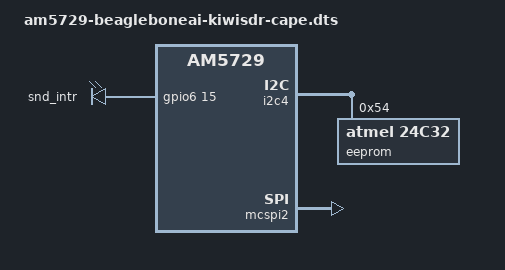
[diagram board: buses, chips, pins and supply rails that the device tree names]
/*
 * Copyright (C) 2014-2019 Texas Instruments Incorporated - http://www.ti.com/
 *
 * This program is free software; you can redistribute it and/or modify
 * it under the terms of the GNU General Public License version 2 as
 * published by the Free Software Foundation.
 */

#include "am5729-beagleboneai.dts"

#define KiwiSDR

    #define OUTPUT_SLOW         (1 << 19)

#ifdef KiwiSDR
    #define PIN_SPI_CS0         (OUTPUT_SLOW | PIN_OUTPUT_PULLUP)
    #define PIN_SPI_CLK	        (OUTPUT_SLOW | PIN_INPUT_PULLUP)
    #define PIN_SPI_MOSI        (OUTPUT_SLOW | PIN_OUTPUT_PULLDOWN)
    #define PIN_SPI_MISO        (PIN_INPUT_PULLDOWN)
#endif

/ {
	chosen {
		base_dtb = "am5729-beagleboneai-kiwisdr-cape.dts";
		base_dtb_timestamp = __TIMESTAMP__;
	};

	kiwisdr {
		compatible = "gpio-leds";
		pinctrl-names = "default";
		pinctrl-0 = <&cape_pins_kiwi>;

		snd_intr {
			label = "snd_intr";
			gpios = <&gpio6 15 GPIO_ACTIVE_HIGH>;
			default-state = "off";
		};
	};
};

&cape_pins {
	status = "disabled";
};

&dra7_pmx_core {
	cape_pins_kiwi: cape_pins_kiwi {
		pinctrl-single,pins = <
		
		// P8 connector
			DRA7XX_CORE_IOPAD(0x379C, PIN_INPUT_PULLUP | MUX_MODE14)    // AB8  P8.3    gpio1_24
			DRA7XX_CORE_IOPAD(0x37A0, PIN_INPUT_PULLUP | MUX_MODE14)    // AB5  P8.4    gpio1_25
			DRA7XX_CORE_IOPAD(0x378C, PIN_INPUT_PULLUP | MUX_MODE14)    // AC9  P8.5    gpio7_1
			DRA7XX_CORE_IOPAD(0x3790, PIN_INPUT_PULLUP | MUX_MODE14)    // AC3  P8.6    gpio7_2
			DRA7XX_CORE_IOPAD(0x36EC, PIN_INPUT_PULLUP | MUX_MODE14)    // G14  P8.7    gpio6_5  jtag tdi
			DRA7XX_CORE_IOPAD(0x36F0, PIN_INPUT_PULLUP | MUX_MODE14)    // F14  P8.8    gpio6_6  jtag td0
			DRA7XX_CORE_IOPAD(0x3698, PIN_INPUT_PULLUP | MUX_MODE14)    // E17  P8.9    gpio6_18 jtag tck
			DRA7XX_CORE_IOPAD(0x36E8, PIN_INPUT_PULLUP | MUX_MODE14)    // A13  P8.10   gpio6_4  jtag tms
			DRA7XX_CORE_IOPAD(0x3510, PIN_INPUT_PULLUP | MUX_MODE14)    // AH4  P8.11   gpio3_11 p811
			DRA7XX_CORE_IOPAD(0x350C, PIN_INPUT_PULLUP | MUX_MODE14)    // AG6  P8.12   gpio3_10 p812
			DRA7XX_CORE_IOPAD(0x3590, PIN_INPUT_PULLUP | MUX_MODE14)    // D3   P8.13   gpio4_11 p813
			DRA7XX_CORE_IOPAD(0x3598, PIN_INPUT_PULLUP | MUX_MODE14)    // D5   P8.14   gpio4_13 p814
			DRA7XX_CORE_IOPAD(0x3570, PIN_INPUT_PULLUP | MUX_MODE14)    // D1   P8.15a  gpio4_3  p815
			DRA7XX_CORE_IOPAD(0x35B4, PULL_DIS | MUX_MODE15)            // A3   P8.15b  gpio4_27
			DRA7XX_CORE_IOPAD(0x35BC, PIN_INPUT_PULLUP | MUX_MODE14)    // B4   P8.16   gpio4_29 p816
			DRA7XX_CORE_IOPAD(0x3624, PIN_INPUT_PULLUP | MUX_MODE14)    // A7   P8.17   gpio8_18 p817
			DRA7XX_CORE_IOPAD(0x3588, PIN_INPUT_PULLUP | MUX_MODE14)    // F5   P8.18   gpio4_9  p818
			DRA7XX_CORE_IOPAD(0x358C, PIN_INPUT_PULLUP | MUX_MODE14)    // E6   P8.19   gpio4_10 p819
			DRA7XX_CORE_IOPAD(0x3780, PIN_INPUT_PULLUP | MUX_MODE14)    // AC4  P8.20   gpio6_30
			DRA7XX_CORE_IOPAD(0x377C, PIN_INPUT_PULLUP | MUX_MODE14)    // AD4  P8.21   gpio6_29
			DRA7XX_CORE_IOPAD(0x3798, PIN_INPUT_PULLUP | MUX_MODE14)    // AD6  P8.22   gpio1_23
			DRA7XX_CORE_IOPAD(0x3794, PIN_INPUT_PULLUP | MUX_MODE14)    // AC8  P8.23   gpio1_22
			DRA7XX_CORE_IOPAD(0x3788, PIN_INPUT_PULLUP | MUX_MODE14)    // AC6  P8.24   gpio7_0
			DRA7XX_CORE_IOPAD(0x3784, PIN_INPUT_PULLUP | MUX_MODE14)    // AC7  P8.25   gpio6_31
			DRA7XX_CORE_IOPAD(0x35B8, PIN_INPUT_PULLUP | MUX_MODE14)    // B3   P8.26   gpio4_28 p826
			DRA7XX_CORE_IOPAD(0x35D8, PIN_INPUT_PULLUP | MUX_MODE14)    // E11  P8.27a  gpio4_23
			DRA7XX_CORE_IOPAD(0x3628, PIN_INPUT_PULLUP | MUX_MODE14)    // A8   P8.27b  gpio8_19
			DRA7XX_CORE_IOPAD(0x35C8, PIN_INPUT_PULLUP | MUX_MODE14)    // D11  P8.28a  gpio4_19
			DRA7XX_CORE_IOPAD(0x362C, PIN_INPUT_PULLUP | MUX_MODE14)    // C9   P8.28b  gpio8_20
			DRA7XX_CORE_IOPAD(0x35D4, PIN_INPUT_PULLUP | MUX_MODE14)    // C11  P8.29a  gpio4_22
			DRA7XX_CORE_IOPAD(0x3630, PIN_INPUT_PULLUP | MUX_MODE14)    // A9   P8.29b  gpio8_21
			DRA7XX_CORE_IOPAD(0x35CC, PIN_INPUT_PULLUP | MUX_MODE14)    // B10  P8.30a  gpio4_20
			DRA7XX_CORE_IOPAD(0x3634, PIN_INPUT_PULLUP | MUX_MODE14)    // B9   P8.30b  gpio8_22
			DRA7XX_CORE_IOPAD(0x3614, PIN_INPUT_PULLUP | MUX_MODE14)    // C8   P8.31a  gpio8_14
			DRA7XX_CORE_IOPAD(0x373C, PULL_DIS | MUX_MODE15)            // G16  P8.31b 
			DRA7XX_CORE_IOPAD(0x3618, PIN_INPUT_PULLUP | MUX_MODE14)    // C7   P8.32a  gpio8_15
			DRA7XX_CORE_IOPAD(0x3740, PULL_DIS | MUX_MODE15)            // D17  P8.32b 
			DRA7XX_CORE_IOPAD(0x3610, PIN_INPUT_PULLUP | MUX_MODE14)    // C6   P8.33a  gpio8_13
			DRA7XX_CORE_IOPAD(0x34E8, PIN_INPUT_PULLUP | MUX_MODE14)    // AF9  P8.33b  gpio3_1
			DRA7XX_CORE_IOPAD(0x3608, PIN_INPUT_PULLUP | MUX_MODE14)    // D8   P8.34a  gpio8_11
			DRA7XX_CORE_IOPAD(0x3564, PIN_INPUT_PULLUP | MUX_MODE14)    // G6   P8.34b  gpio4_0
			DRA7XX_CORE_IOPAD(0x360C, PIN_INPUT_PULLUP | MUX_MODE14)    // A5   P8.35a  gpio8_12
			DRA7XX_CORE_IOPAD(0x34E4, PIN_INPUT_PULLUP | MUX_MODE14)    // AD9  P8.35b  gpio3_0
			DRA7XX_CORE_IOPAD(0x3604, PIN_INPUT_PULLUP | MUX_MODE14)    // D7   P8.36a  gpio8_10
			DRA7XX_CORE_IOPAD(0x3568, PIN_INPUT_PULLUP | MUX_MODE14)    // F2   P8.36b  gpio4_1
			DRA7XX_CORE_IOPAD(0x35FC, PIN_INPUT_PULLUP | MUX_MODE14)    // E8   P8.37a  gpio8_8
			DRA7XX_CORE_IOPAD(0x3738, PULL_DIS | MUX_MODE15)            // A21  P8.37b 
			DRA7XX_CORE_IOPAD(0x3600, PIN_INPUT_PULLUP | MUX_MODE14)    // D9   P8.38a  gpio8_9
			DRA7XX_CORE_IOPAD(0x3734, PULL_DIS | MUX_MODE15)            // C18  P8.38b 
			DRA7XX_CORE_IOPAD(0x35F4, PIN_INPUT_PULLUP | MUX_MODE14)    // F8   P8.39   gpio8_6
			DRA7XX_CORE_IOPAD(0x35F8, PIN_INPUT_PULLUP | MUX_MODE14)    // E7   P8.40   gpio8_7
			DRA7XX_CORE_IOPAD(0x35EC, PIN_INPUT_PULLUP | MUX_MODE14)    // E9   P8.41   gpio8_4
			DRA7XX_CORE_IOPAD(0x35F0, PIN_INPUT_PULLUP | MUX_MODE14)    // F9   P8.42   gpio8_5
			DRA7XX_CORE_IOPAD(0x35E4, PIN_INPUT_PULLUP | MUX_MODE14)    // F10  P8.43   gpio8_2
			DRA7XX_CORE_IOPAD(0x35E8, PIN_INPUT_PULLUP | MUX_MODE14)    // G11  P8.44   gpio8_3
			DRA7XX_CORE_IOPAD(0x35DC, PIN_INPUT_PULLUP | MUX_MODE14)    // F11  P8.45a  gpio8_0
			DRA7XX_CORE_IOPAD(0x361C, PIN_INPUT_PULLUP | MUX_MODE14)    // B7   P8.45b  gpio8_16
			DRA7XX_CORE_IOPAD(0x35E0, PIN_INPUT_PULLUP | MUX_MODE14)    // G10  P8.46a  gpio8_1
			DRA7XX_CORE_IOPAD(0x3638, PIN_INPUT_PULLUP | MUX_MODE14)    // A10  P8.46b  gpio8_23

        // P9 connector
			DRA7XX_CORE_IOPAD(0x372C, PULL_DIS | MUX_MODE15)            // B19  P9.11a  
			DRA7XX_CORE_IOPAD(0x3620, PIN_INPUT_PULLDOWN | MUX_MODE14)  // B8   P9.11b  gpio8_17 p911
			DRA7XX_CORE_IOPAD(0x36AC, PIN_OUTPUT_PULLUP | MUX_MODE14)   // B14  P9.12   gpio5_0 fpga_pgm
			DRA7XX_CORE_IOPAD(0x3730, MUX_MODE15)                       // C17  P9.13a  
			DRA7XX_CORE_IOPAD(0x3680, PIN_INPUT_PULLDOWN | MUX_MODE14)  // AB10 P9.13b  gpio6_12 p913 (not connected on rev A1)
			DRA7XX_CORE_IOPAD(0x35AC, PIN_INPUT_PULLUP | MUX_MODE14)    // D6   P9.14   gpio4_25 fpga_init
			DRA7XX_CORE_IOPAD(0x3514, PIN_INPUT_PULLUP | MUX_MODE14)    // AG4  P9.15   gpio3_12 p915

            // spi2
			DRA7XX_CORE_IOPAD(0x35B0, PIN_OUTPUT_PULLUP | MUX_MODE14)   // C5   P9.16   gpio4_26 spi2_cs1
			DRA7XX_CORE_IOPAD(0x37CC, PIN_SPI_CS0 | MUX_MODE0)          // B24  P9.17a  spi2_cs0
			DRA7XX_CORE_IOPAD(0x36B8, PULL_DIS | MUX_MODE15)            // F12  P9.17b  
			DRA7XX_CORE_IOPAD(0x37C8, PIN_SPI_MOSI | MUX_MODE0)         // G17  P9.18a  spi2_d0 mosi
			DRA7XX_CORE_IOPAD(0x36B4, PULL_DIS | MUX_MODE15)            // G12  P9.18b  

            // i2c4 config eeproms: AI board and Kiwi cape
			DRA7XX_CORE_IOPAD(0x3440, PIN_INPUT_PULLUP | MUX_MODE7)     // R6   P9.19a  i2c4_scl
			DRA7XX_CORE_IOPAD(0x357C, PULL_DIS | MUX_MODE15)            // F4   P9.19b 
			DRA7XX_CORE_IOPAD(0x3444, PIN_INPUT_PULLUP | MUX_MODE7)     // T9   P9.20a  i2c4_sda
			DRA7XX_CORE_IOPAD(0x3578, PULL_DIS | MUX_MODE15)            // D2   P9.20b  

            // spi2
			DRA7XX_CORE_IOPAD(0x34F0, PULL_DIS | MUX_MODE15)            // AF8  P9.21a  
			DRA7XX_CORE_IOPAD(0x37C4, PIN_SPI_MISO | MUX_MODE0)         // B22  P9.21b  spi2_d1 miso
			DRA7XX_CORE_IOPAD(0x369C, PULL_DIS | MUX_MODE15)            // B26  P9.22a  
			DRA7XX_CORE_IOPAD(0x37C0, PIN_SPI_CLK | MUX_MODE0)          // A26  P9.22b  spi2_sclk

			DRA7XX_CORE_IOPAD(0x37B4, PIN_INPUT | MUX_MODE14)           // A22  P9.23   gpio7_11 p923
			DRA7XX_CORE_IOPAD(0x368C, PIN_INPUT | MUX_MODE14)           // F20  P9.24   gpio6_15 snd_intr
			DRA7XX_CORE_IOPAD(0x3694, PIN_INPUT | MUX_MODE14)           // D18  P9.25   gpio6_17
			DRA7XX_CORE_IOPAD(0x3688, PIN_INPUT | MUX_MODE14)           // E21  P9.26a  gpio6_14 p926
			DRA7XX_CORE_IOPAD(0x3544, MUX_MODE15)                       // AE2  P9.26b  gpio3_24
			DRA7XX_CORE_IOPAD(0x35A0, PIN_INPUT | MUX_MODE14)           // C3   P9.27a  gpio4_15 lcd
			DRA7XX_CORE_IOPAD(0x36B0, MUX_MODE15)                       // J14  P9.27b  gpio5_1 lcd
			DRA7XX_CORE_IOPAD(0x36E0, PIN_INPUT | MUX_MODE14)           // A12  P9.28   gpio4_17 lcd
			DRA7XX_CORE_IOPAD(0x36D8, PIN_INPUT | MUX_MODE14)           // A11  P9.29a  gpio5_11 lcd
			DRA7XX_CORE_IOPAD(0x36A8, MUX_MODE15)                       // D14  P9.29b  gpio7_30 lcd
			DRA7XX_CORE_IOPAD(0x36DC, PIN_INPUT | MUX_MODE14)           // B13  P9.30   gpio5_12 lcd
			DRA7XX_CORE_IOPAD(0x36D4, PIN_INPUT | MUX_MODE14)           // B12  P9.31a  gpio5_10 lcd
			DRA7XX_CORE_IOPAD(0x36A4, MUX_MODE15)                       // C14  P9.31b  gpio7_31 lcd
			DRA7XX_CORE_IOPAD(0x36A0, PIN_INPUT | MUX_MODE14)           // C23  P9.41a  gpio6_20 lcd
			DRA7XX_CORE_IOPAD(0x3580, MUX_MODE15)                       // C1   P9.41b  gpio4_7 lcd
			DRA7XX_CORE_IOPAD(0x36E4, MUX_MODE15)                       // E14  P9.42a  gpio4_18 lcd
			DRA7XX_CORE_IOPAD(0x359C, PIN_INPUT | MUX_MODE14)           // C2   P9.42b  gpio4_14 lcd
		>;
	};
};

&i2c4 {
	eeprom: eeprom@54 {
		compatible = "atmel,24c32";
		reg = <0x54>;
	};
};

&mcspi2 {
	#address-cells = <1>;
	#size-cells = <0>;
	status = "okay";
	ti,pindir-d0-out-d1-in;

	cs-gpios = <0>, <&gpio7 11 0>;

	channel@0 {
		#address-cells = <1>;
		#size-cells = <0>;
		compatible = "spidev";
		reg = <0>;
		spi-max-frequency = <24000000>;
	};

	channel@1 {
		#address-cells = <1>;
		#size-cells = <0>;
		compatible = "spidev";
		reg = <1>;
		spi-max-frequency = <24000000>;
	};
};
